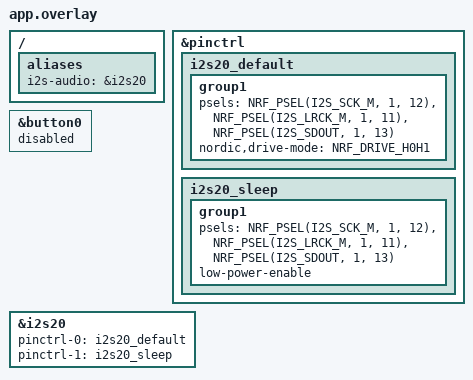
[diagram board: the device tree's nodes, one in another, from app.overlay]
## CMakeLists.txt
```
#
# Copyright (c) 2026 5th Sense
# SPDX-License-Identifier: Apache-2.0
#

cmake_minimum_required(VERSION 3.20.0)

find_package(Zephyr REQUIRED HINTS $ENV{ZEPHYR_BASE})
project(nrf54l15_audio_receiver)

target_sources(app PRIVATE
    src/main.c
    src/audio_i2s.c
    src/audio_stream_service.c
    src/jitter_buffer.c
    src/flash_storage.c
    src/audio_dsp.c
    src/tone_synth.c
    src/adpcm.c
    src/lc3/lc3_dec.c
    src/lc3/lc3_tables.c
)

target_include_directories(app PRIVATE src src/lc3)
```

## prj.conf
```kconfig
#
# Copyright (c) 2026 5th Sense
# nRF54L15 Audio Receiver Configuration
#

# General System & Kernel
CONFIG_MAIN_STACK_SIZE=4096
CONFIG_SYSTEM_WORKQUEUE_STACK_SIZE=4096
CONFIG_BT_RX_STACK_SIZE=4096
CONFIG_HEAP_MEM_POOL_SIZE=32768
CONFIG_FPU=y
CONFIG_EVENTS=y
CONFIG_RING_BUFFER=y

# Logging & Assertions
CONFIG_LOG=y
CONFIG_LOG_DEFAULT_LEVEL=3
CONFIG_LOG_BUFFER_SIZE=4096
CONFIG_CBPRINTF_FP_SUPPORT=y
CONFIG_ASSERT=y

# Bluetooth LE Configuration
CONFIG_BT=y
CONFIG_BT_PERIPHERAL=y
CONFIG_BT_DEVICE_NAME="nRF54L15-Audio-Sink"
CONFIG_BT_DEVICE_APPEARANCE=2064
CONFIG_BT_MAX_CONN=1
CONFIG_BT_MAX_PAIRED=1

# High-Throughput BLE Parameters (16x 502-byte hardware packet buffers)
CONFIG_BT_BUF_ACL_RX_COUNT=16
CONFIG_BT_BUF_ACL_TX_COUNT=16
CONFIG_BT_BUF_ACL_RX_SIZE=502
CONFIG_BT_BUF_ACL_TX_SIZE=502
CONFIG_BT_L2CAP_TX_MTU=498
CONFIG_BT_CTLR_DATA_LENGTH_MAX=251
CONFIG_BT_USER_DATA_LEN_UPDATE=y
CONFIG_BT_USER_PHY_UPDATE=y
CONFIG_BT_AUTO_PHY_UPDATE=y
CONFIG_BT_AUTO_DATA_LEN_UPDATE=y
CONFIG_BT_GATT_CLIENT=n
CONFIG_BT_GATT_DYNAMIC_DB=y

# Bluetooth Controller Tuning for High Data Rate
CONFIG_BT_CTLR_TX_PWR_PLUS_8=y

# I2S Driver for MAX98357A
CONFIG_I2S=y
CONFIG_I2S_NRFX=y

# Flash Storage & LittleFS (For Onboard/External Flash)
CONFIG_FLASH=y
CONFIG_FLASH_MAP=y
CONFIG_FLASH_PAGE_LAYOUT=y
CONFIG_FILE_SYSTEM=y
CONFIG_FILE_SYSTEM_LITTLEFS=y
CONFIG_NORDIC_QSPI_NOR=y
CONFIG_SPI_NOR=y

# Power Management
CONFIG_PM=y
CONFIG_PM_DEVICE=y

# GPIO & Pin Control
CONFIG_GPIO=y
CONFIG_PINCTRL=y
```

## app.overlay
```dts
/*
 * Copyright (c) 2026 5th Sense
 * DeviceTree Overlay for nRF54L15 Audio Receiver with MAX98357A & Storage
 */

/ {
	aliases {
		i2s-audio = &i2s20;
	};
};

/* Pin control configuration for I2S output to MAX98357A */
&pinctrl {
	i2s20_default: i2s20_default {
		group1 {
			psels = <NRF_PSEL(I2S_SCK_M, 1, 12)>,
				<NRF_PSEL(I2S_LRCK_M, 1, 11)>,
				<NRF_PSEL(I2S_SDOUT, 1, 13)>;
			nordic,drive-mode = <NRF_DRIVE_H0H1>;
		};
	};

	i2s20_sleep: i2s20_sleep {
		group1 {
			psels = <NRF_PSEL(I2S_SCK_M, 1, 12)>,
				<NRF_PSEL(I2S_LRCK_M, 1, 11)>,
				<NRF_PSEL(I2S_SDOUT, 1, 13)>;
			low-power-enable;
		};
	};
};

/* Disable button0 on P1.13 so P1.13 is fully dedicated to I2S DIN */
&button0 {
	status = "disabled";
};

/* Enable I2S20 peripheral */
&i2s20 {
	status = "okay";
	pinctrl-0 = <&i2s20_default>;
	pinctrl-1 = <&i2s20_sleep>;
	pinctrl-names = "default", "sleep";
};
```

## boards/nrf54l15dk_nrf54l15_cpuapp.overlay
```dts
/*
 * Copyright (c) 2026 5th Sense
 * Board specific overlay for nRF54L15 DK (PCA10156)
 */

#include "../app.overlay"
```

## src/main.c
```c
/*
 * Copyright (c) 2026 5th Sense
 * nRF54L15 Audio Receiver Main Application
 */

#include <zephyr/kernel.h>
#include <zephyr/logging/log.h>
#include <zephyr/bluetooth/bluetooth.h>
#include <zephyr/bluetooth/conn.h>
#include <zephyr/bluetooth/uuid.h>
#include <zephyr/bluetooth/gatt.h>
#include <zephyr/drivers/gpio.h>

#include "audio_protocol.h"
#include "audio_dsp.h"
#include "jitter_buffer.h"
#include "audio_i2s.h"
#include "flash_storage.h"
#include "audio_stream_service.h"
#include "tone_synth.h"

LOG_MODULE_REGISTER(main, LOG_LEVEL_INF);

/* LED Status Indicator aliases if present on board */
#define LED0_NODE DT_ALIAS(led0)
#define LED1_NODE DT_ALIAS(led1)

#if DT_NODE_HAS_STATUS(LED0_NODE, okay)
static const struct gpio_dt_spec led_conn = GPIO_DT_SPEC_GET(LED0_NODE, gpios);
#endif
#if DT_NODE_HAS_STATUS(LED1_NODE, okay)
static const struct gpio_dt_spec led_play = GPIO_DT_SPEC_GET(LED1_NODE, gpios);
#endif

void main_set_conn_led(bool active)
{
#if DT_NODE_HAS_STATUS(LED0_NODE, okay)
	if (device_is_ready(led_conn.port)) {
		gpio_pin_set_dt(&led_conn, active ? 1 : 0);
	}
#endif
}

void main_set_playback_led(bool active)
{
#if DT_NODE_HAS_STATUS(LED1_NODE, okay)
	if (device_is_ready(led_play.port)) {
		gpio_pin_set_dt(&led_play, active ? 1 : 0);
	}
#endif
}

/* Physical Hardware Buttons from Schematic:
 * SW2 (Button0) = P1.13 (Connected to MAX98357A I2S DIN)
 * SW3 (Button1) = P1.09
 * SW5 (Button2) = P1.08
 * SW6 (Button3) = P0.04
 */
static const struct device *g_gpio0_dev = NULL;
static const struct device *g_gpio1_dev = NULL;
static struct gpio_callback g_btn_cb_gpio1;
static struct gpio_callback g_btn_cb_gpio0;

static int64_t last_button_time = 0;

static void trigger_diagnostic_tune(const char *btn_name)
{
	int64_t now = k_uptime_get();
	if (now - last_button_time < 400) {
		return; /* Debounce 400ms */
	}
	last_button_time = now;

	LOG_INF("[%s Pressed] Playing Diagnostic Melody...", btn_name);
	tone_synth_play_button2_tune();
}

static void button_pressed_cb(const struct device *dev, struct gpio_callback *cb, uint32_t pins)
{
	ARG_UNUSED(cb);

	if (dev == g_gpio1_dev) {
		if (pins & BIT(9)) {
			trigger_diagnostic_tune("SW3 (Button1 / P1.09)");
		} else if (pins & BIT(8)) {
			trigger_diagnostic_tune("SW5 (Button2 / P1.08)");
		}
	} else if (dev == g_gpio0_dev) {
		if (pins & BIT(4)) {
			trigger_diagnostic_tune("SW6 (Button3 / P0.04)");
		}
	}
}

/* BLE Advertising Data */
static const struct bt_data ad[] = {
	BT_DATA_BYTES(BT_DATA_FLAGS, (BT_LE_AD_GENERAL | BT_LE_AD_NO_BREDR)),
	BT_DATA(BT_DATA_NAME_COMPLETE, CONFIG_BT_DEVICE_NAME, sizeof(CONFIG_BT_DEVICE_NAME) - 1),
};

static const struct bt_data sd[] = {
	BT_DATA_BYTES(BT_DATA_UUID128_ALL, BT_UUID_AUDIO_SERVICE_VAL),
	BT_DATA_BYTES(BT_DATA_GAP_APPEARANCE, 0x10, 0x08), /* Generic Media Player / Audio Sink */
};

/* Fast connection parameters: 15ms interval, 0 latency, 4000ms supervision timeout */
static const struct bt_le_conn_param conn_param_fast = {
	.interval_min = BT_GAP_MS_TO_CONN_INTERVAL(15),
	.interval_max = BT_GAP_MS_TO_CONN_INTERVAL(20),
	.latency = 0,
	.timeout = 400,
};

static bool g_is_connected = false;

static void start_advertising(void)
{
	int ret = bt_le_adv_start(BT_LE_ADV_CONN, ad, ARRAY_SIZE(ad), sd, ARRAY_SIZE(sd));
	if (ret && ret != -EALREADY) {
		bt_le_adv_stop();
		ret = bt_le_adv_start(BT_LE_ADV_CONN, ad, ARRAY_SIZE(ad), sd, ARRAY_SIZE(sd));
	}
	if (!ret) {
		LOG_INF("BLE Advertising active as '%s'", CONFIG_BT_DEVICE_NAME);
	}
}

static void connected_cb(struct bt_conn *conn, uint8_t err)
{
	char addr[BT_ADDR_LE_STR_LEN];
	bt_addr_le_to_str(bt_conn_get_dst(conn), addr, sizeof(addr));

	if (err) {
		LOG_ERR("Connection failed (err 0x%02x): %s", err, addr);
		return;
	}

	g_is_connected = true;
	LOG_INF("Connected to peer: %s", addr);

#if DT_NODE_HAS_STATUS(LED0_NODE, okay)
	if (device_is_ready(led_conn.port)) {
		gpio_pin_set_dt(&led_conn, 1);
	}
#endif

	audio_stream_service_on_connected(conn);
}

static void disconnected_cb(struct bt_conn *conn, uint8_t reason)
{
	char addr[BT_ADDR_LE_STR_LEN];
	bt_addr_le_to_str(bt_conn_get_dst(conn), addr, sizeof(addr));

	g_is_connected = false;
	LOG_INF("Disconnected from %s (reason 0x%02x)", addr, reason);

#if DT_NODE_HAS_STATUS(LED0_NODE, okay)
	if (device_is_ready(led_conn.port)) {
		gpio_pin_set_dt(&led_conn, 0);
	}
#endif
#if DT_NODE_HAS_STATUS(LED1_NODE, okay)
	if (device_is_ready(led_play.port)) {
		gpio_pin_set_dt(&led_play, 0);
	}
#endif

	audio_stream_service_on_disconnected(conn);

	/* Restart advertising */
	start_advertising();
}

static void le_phy_updated_cb(struct bt_conn *conn, struct bt_conn_le_phy_info *param)
{
	LOG_INF("LE PHY Updated: TX=%u, RX=%u", param->tx_phy, param->rx_phy);
}

static void le_data_len_updated_cb(struct bt_conn *conn, struct bt_conn_le_data_len_info *info)
{
	LOG_INF("LE Data Length Updated: TX max=%u bytes, RX max=%u bytes",
		info->tx_max_len, info->rx_max_len);
}

BT_CONN_CB_DEFINE(conn_callbacks) = {
	.connected = connected_cb,
	.disconnected = disconnected_cb,
	.le_phy_updated = le_phy_updated_cb,
	.le_data_len_updated = le_data_len_updated_cb,
};

int main(void)
{
	LOG_INF("==================================================");
	LOG_INF("  5th Sense nRF54L15 Audio Receiver & Streamer    ");
	LOG_INF("  Target: nRF54L15 Dev Module + MAX98357A I2S     ");
	LOG_INF("==================================================");

	/* 1. Init LEDs */
#if DT_NODE_HAS_STATUS(LED0_NODE, okay)
	if (device_is_ready(led_conn.port)) {
		gpio_pin_configure_dt(&led_conn, GPIO_OUTPUT_INACTIVE);
	}
#endif
#if DT_NODE_HAS_STATUS(LED1_NODE, okay)
	if (device_is_ready(led_play.port)) {
		gpio_pin_configure_dt(&led_play, GPIO_OUTPUT_INACTIVE);
	}
#endif

	/* 2. Init Buttons: SW3 (P1.09), SW5 (P1.08), SW6 (P0.04) */
	g_gpio1_dev = DEVICE_DT_GET(DT_NODELABEL(gpio1));
	g_gpio0_dev = DEVICE_DT_GET(DT_NODELABEL(gpio0));

	if (g_gpio1_dev && device_is_ready(g_gpio1_dev)) {
		/* SW3 (Button1 / P1.09) */
		gpio_pin_configure(g_gpio1_dev, 9, GPIO_INPUT | GPIO_PULL_UP);
		gpio_pin_interrupt_configure(g_gpio1_dev, 9, GPIO_INT_EDGE_FALLING);

		/* SW5 (Button2 / P1.08) */
		gpio_pin_configure(g_gpio1_dev, 8, GPIO_INPUT | GPIO_PULL_UP);
		gpio_pin_interrupt_configure(g_gpio1_dev, 8, GPIO_INT_EDGE_FALLING);

		gpio_init_callback(&g_btn_cb_gpio1, button_pressed_cb, BIT(9) | BIT(8));
		gpio_add_callback(g_gpio1_dev, &g_btn_cb_gpio1);
		LOG_INF("Buttons SW3 (P1.09) and SW5 (P1.08) configured");
	}

	if (g_gpio0_dev && device_is_ready(g_gpio0_dev)) {
		/* SW6 (Button3 / P0.04) */
		gpio_pin_configure(g_gpio0_dev, 4, GPIO_INPUT | GPIO_PULL_UP);
		gpio_pin_interrupt_configure(g_gpio0_dev, 4, GPIO_INT_EDGE_FALLING);

		gpio_init_callback(&g_btn_cb_gpio0, button_pressed_cb, BIT(4));
		gpio_add_callback(g_gpio0_dev, &g_btn_cb_gpio0);
		LOG_INF("Button SW6 (P0.04) configured");
	}

	/* 3. Init Audio DSP & Jitter Buffer */
	audio_dsp_init();
	jitter_buffer_init();

	/* 4. Init Flash Storage */
	int ret = flash_storage_init();
	if (ret == 0) {
		LOG_INF("Flash storage ready for audio asset caching");
	}

	/* 5. Init I2S Driver for MAX98357A */
	ret = audio_i2s_init();
	if (ret != 0) {
		LOG_ERR("Failed to initialize I2S interface: %d", ret);
	}

	/* 6. Init Tone & Melody Synthesizer */
	tone_synth_init();

	/* 7. Init Audio GATT Service */
	audio_stream_service_init();

	/* 8. Enable Bluetooth */
	ret = bt_enable(NULL);
	if (ret) {
		LOG_ERR("Bluetooth init failed (err %d)", ret);
		return ret;
	}
	LOG_INF("Bluetooth initialized successfully");

	/* 9. Start Advertising */
	start_advertising();

	/* 10. Play Startup Boot Tune on MAX98357A I2S DAC */
	k_msleep(150);
	tone_synth_play_startup_tune();

	/* 11. Housekeeping, Polling & Stats Loop */
	int stats_counter = 0;
	while (1) {
		k_msleep(50);

		/* Button Polling backup (Grounded when pressed -> raw value 0) */
		if (g_gpio1_dev && device_is_ready(g_gpio1_dev)) {
			if (gpio_pin_get_raw(g_gpio1_dev, 9) == 0) {
				trigger_diagnostic_tune("SW3 (Button1 / P1.09)");
			} else if (gpio_pin_get_raw(g_gpio1_dev, 8) == 0) {
				trigger_diagnostic_tune("SW5 (Button2 / P1.08)");
			}
		}
		if (g_gpio0_dev && device_is_ready(g_gpio0_dev)) {
			if (gpio_pin_get_raw(g_gpio0_dev, 4) == 0) {
				trigger_diagnostic_tune("SW6 (Button3 / P0.04)");
			}
		}

		stats_counter++;
		if (stats_counter >= 10) { /* Every 500ms */
			stats_counter = 0;

			/* Watchdog: If disconnected, ensure advertising is continuously running */
			if (!g_is_connected) {
				start_advertising();
			}

			/* Update Play LED */
#if DT_NODE_HAS_STATUS(LED1_NODE, okay)
			if (device_is_ready(led_play.port)) {
				gpio_pin_set_dt(&led_play, audio_i2s_is_active() ? 1 : 0);
			}
#endif
			/* Send periodic stats to connected phone */
			audio_stream_service_send_stats();
		}
	}

	return 0;
}
```

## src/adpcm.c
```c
/*
 * Copyright (c) 2026 5th Sense
 * IMA-ADPCM Audio Decoder Implementation
 */

#include "adpcm.h"

/* Standard IMA-ADPCM Step Table (89 entries) */
static const int16_t step_table[89] = {
	7, 8, 9, 10, 11, 12, 13, 14, 16, 17,
	19, 21, 23, 25, 28, 31, 34, 37, 41, 45,
	50, 55, 60, 66, 73, 80, 88, 97, 107, 118,
	130, 143, 157, 173, 190, 209, 230, 253, 279, 307,
	337, 371, 408, 449, 494, 544, 598, 658, 724, 796,
	876, 963, 1060, 1166, 1282, 1411, 1552, 1707, 1878, 2066,
	2272, 2499, 2749, 3024, 3327, 3660, 4026, 4428, 4871, 5358,
	5894, 6484, 7132, 7845, 8630, 9493, 10442, 11487, 12635, 13899,
	15289, 16818, 18500, 20350, 22385, 24623, 27086, 29794, 32767
};

/* Standard IMA-ADPCM Index Table for 4-bit nibbles */
static const int8_t index_table[16] = {
	-1, -1, -1, -1, 2, 4, 6, 8,
	-1, -1, -1, -1, 2, 4, 6, 8
};

static inline int16_t decode_sample(uint8_t nibble, int16_t *predictor, int8_t *step_index)
{
	int16_t step = step_table[*step_index];
	int32_t diff = step >> 3;

	if (nibble & 4) diff += step;
	if (nibble & 2) diff += (step >> 1);
	if (nibble & 1) diff += (step >> 2);

	int32_t pred = *predictor;
	if (nibble & 8) {
		pred -= diff;
	} else {
		pred += diff;
	}

	/* Clamp to 16-bit signed range */
	if (pred > 32767) pred = 32767;
	else if (pred < -32768) pred = -32768;

	*predictor = (int16_t)pred;

	/* Update step index */
	int8_t idx = *step_index + index_table[nibble & 0x0F];
	if (idx < 0) idx = 0;
	else if (idx > 88) idx = 88;
	*step_index = idx;

	return *predictor;
}

size_t adpcm_decode_frame(const uint8_t *adpcm_data, size_t adpcm_len,
                          int16_t init_predictor, uint8_t init_index,
                          int16_t *out_pcm)
{
	if (!adpcm_data || !out_pcm || adpcm_len == 0) {
		return 0;
	}

	int16_t predictor = init_predictor;
	int8_t step_index = (int8_t)(init_index > 88 ? 88 : init_index);
	size_t out_idx = 0;

	for (size_t i = 0; i < adpcm_len; i++) {
		uint8_t byte = adpcm_data[i];

		/* Lower nibble first */
		out_pcm[out_idx++] = decode_sample(byte & 0x0F, &predictor, &step_index);

		/* Upper nibble second */
		out_pcm[out_idx++] = decode_sample((byte >> 4) & 0x0F, &predictor, &step_index);
	}

	return out_idx;
}
```

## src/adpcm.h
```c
/*
 * Copyright (c) 2026 5th Sense
 * IMA-ADPCM Audio Codec for Ultra-Low Latency BLE Streaming
 */

#ifndef ADPCM_H_
#define ADPCM_H_

#include <stdint.h>
#include <stddef.h>

#ifdef __cplusplus
extern "C" {
#endif

/*
 * Decode IMA-ADPCM buffer into 16-bit linear PCM
 *
 * @param adpcm_data: Pointer to packed 4-bit ADPCM nibbles
 * @param adpcm_len: Length of adpcm_data in bytes
 * @param init_predictor: Initial 16-bit predictor sample from packet header
 * @param init_index: Initial step index (0-88) from packet header
 * @param out_pcm: Output buffer for 16-bit PCM samples (must hold adpcm_len * 2 samples)
 * @return Number of 16-bit PCM samples generated (adpcm_len * 2)
 */
size_t adpcm_decode_frame(const uint8_t *adpcm_data, size_t adpcm_len,
                          int16_t init_predictor, uint8_t init_index,
                          int16_t *out_pcm);

#ifdef __cplusplus
}
#endif

#endif /* ADPCM_H_ */
```

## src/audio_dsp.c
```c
/*
 * Copyright (c) 2026 5th Sense
 * Audio DSP Implementation
 */

#include "audio_dsp.h"
#include <zephyr/kernel.h>
#include <zephyr/logging/log.h>

LOG_MODULE_REGISTER(audio_dsp, LOG_LEVEL_INF);

static uint8_t g_volume_percent = 100;
static int32_t g_volume_gain_q15 = 32768; /* 100% default unity gain */

void audio_dsp_init(void)
{
	audio_dsp_set_volume(100);
	LOG_INF("Audio DSP initialized. Default volume: %u%%", g_volume_percent);
}

void audio_dsp_set_volume(uint8_t volume_percent)
{
	if (volume_percent > 100) {
		volume_percent = 100;
	}
	g_volume_percent = volume_percent;

	/* Logarithmic perception curve mapping to Q15 gain */
	/* gain = (vol/100)^2 * 32768 */
	uint32_t vol_squared = (uint32_t)volume_percent * (uint32_t)volume_percent;
	g_volume_gain_q15 = (int32_t)((vol_squared * 32768U) / 10000U);
}

uint8_t audio_dsp_get_volume(void)
{
	return g_volume_percent;
}

void audio_dsp_process_pcm16(int16_t *samples, size_t num_samples)
{
	if (!samples || num_samples == 0) {
		return;
	}

	if (g_volume_percent == 100) {
		return;
	}

	if (g_volume_percent == 0) {
		memset(samples, 0, num_samples * sizeof(int16_t));
		return;
	}

	for (size_t i = 0; i < num_samples; i++) {
		/* Apply Q15 volume gain */
		int32_t sample = (int32_t)samples[i];
		int32_t scaled = (sample * g_volume_gain_q15) >> 15;

		/* Soft limiter / hard clamp to 16-bit range */
		if (scaled > 32767) {
			scaled = 32767;
		} else if (scaled < -32768) {
			scaled = -32768;
		}

		samples[i] = (int16_t)scaled;
	}
}

void audio_dsp_stereo_to_mono(const int16_t *stereo_in, int16_t *mono_out, size_t num_frames)
{
	if (!stereo_in || !mono_out || num_frames == 0) {
		return;
	}

	for (size_t i = 0; i < num_frames; i++) {
		int32_t left = stereo_in[i * 2];
		int32_t right = stereo_in[i * 2 + 1];
		int32_t mixed = (left + right) / 2;
		mono_out[i] = (int16_t)mixed;
	}
}
```

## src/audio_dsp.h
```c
/*
 * Copyright (c) 2026 5th Sense
 * Audio DSP: Volume Scaling, Soft Limiter, Mixing
 */

#ifndef AUDIO_DSP_H_
#define AUDIO_DSP_H_

#include <stdint.h>
#include <stddef.h>

#ifdef __cplusplus
extern "C" {
#endif

void audio_dsp_init(void);
void audio_dsp_set_volume(uint8_t volume_percent);
uint8_t audio_dsp_get_volume(void);

/* Process 16-bit PCM samples in place: apply volume scaling and soft-clipping */
void audio_dsp_process_pcm16(int16_t *samples, size_t num_samples);

/* Downmix 16-bit stereo interleaved samples to mono in-place or out */
void audio_dsp_stereo_to_mono(const int16_t *stereo_in, int16_t *mono_out, size_t num_frames);

#ifdef __cplusplus
}
#endif

#endif /* AUDIO_DSP_H_ */
```

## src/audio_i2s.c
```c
/*
 * Copyright (c) 2026 5th Sense
 * Zephyr I2S Driver Implementation for MAX98357A DAC
 */

#include "audio_i2s.h"
#include "jitter_buffer.h"
#include "audio_dsp.h"
#include <zephyr/kernel.h>
#include <zephyr/drivers/i2s.h>
#include <zephyr/logging/log.h>

LOG_MODULE_REGISTER(audio_i2s, LOG_LEVEL_INF);

/* Memory slab for I2S DMA TX buffers (640 bytes per block, 8 blocks) */
K_MEM_SLAB_DEFINE_STATIC(i2s_tx_slab, I2S_BLOCK_SIZE_BYTES, I2S_NUM_BLOCKS, 4);

/* I2S Thread definitions */
#define I2S_THREAD_STACK_SIZE 2048
#define I2S_THREAD_PRIORITY   1 /* High priority audio thread */

static K_THREAD_STACK_DEFINE(i2s_thread_stack, I2S_THREAD_STACK_SIZE);
static struct k_thread i2s_thread_data;

static const struct device *g_i2s_dev = NULL;
static struct i2s_config g_i2s_cfg;
static bool g_is_running = false;
static bool g_dma_running = false;
static bool g_i2s_configured = false;

static void i2s_playback_thread(void *arg1, void *arg2, void *arg3);

int audio_i2s_init(void)
{
#if DT_NODE_EXISTS(DT_ALIAS(i2s_audio))
	g_i2s_dev = DEVICE_DT_GET(DT_ALIAS(i2s_audio));
#elif DT_NODE_EXISTS(DT_NODELABEL(i2s20))
	g_i2s_dev = DEVICE_DT_GET(DT_NODELABEL(i2s20));
#elif DT_NODE_EXISTS(DT_NODELABEL(i2s0))
	g_i2s_dev = DEVICE_DT_GET(DT_NODELABEL(i2s0));
#else
	LOG_ERR("No I2S device found in DeviceTree!");
	return -ENODEV;
#endif

	if (!g_i2s_dev || !device_is_ready(g_i2s_dev)) {
		LOG_ERR("I2S device %s is not ready!", g_i2s_dev ? g_i2s_dev->name : "NULL");
		return -ENODEV;
	}

	LOG_INF("I2S device %s found and ready", g_i2s_dev->name);

	/* Configure standard Stereo Philips I2S format (16kHz, 16-bit, 2 Channels for MAX98357A) */
	int ret = audio_i2s_configure(16000, 2, 16);
	if (ret < 0) {
		LOG_ERR("Failed to configure I2S default format: %d", ret);
		return ret;
	}

	/* Start dedicated I2S playback feeder thread */
	k_thread_create(&i2s_thread_data, i2s_thread_stack,
			K_THREAD_STACK_SIZEOF(i2s_thread_stack),
			i2s_playback_thread, NULL, NULL, NULL,
			I2S_THREAD_PRIORITY, 0, K_NO_WAIT);
	k_thread_name_set(&i2s_thread_data, "i2s_feeder");

	return 0;
}

int audio_i2s_configure(uint32_t sample_rate, uint8_t channels, uint8_t bit_depth)
{
	(void)channels;
	if (!g_i2s_dev) {
		return -ENODEV;
	}

	/* Force 2 channels (Stereo) for MAX98357A standard Philips clocking */
	uint8_t ch = 2;
	uint8_t ws = (bit_depth == 24) ? 24 : 16;

	if (g_i2s_configured && g_i2s_cfg.frame_clk_freq == sample_rate &&
	    g_i2s_cfg.channels == ch && g_i2s_cfg.word_size == ws) {
		return 0; /* Already configured to matching parameters */
	}

	if (g_dma_running) {
		i2s_trigger(g_i2s_dev, I2S_DIR_TX, I2S_TRIGGER_DROP);
		g_dma_running = false;
	}

	memset(&g_i2s_cfg, 0, sizeof(g_i2s_cfg));

	/* Standard Philips I2S format, Master mode */
	g_i2s_cfg.word_size = ws;
	g_i2s_cfg.channels = ch;
	g_i2s_cfg.format = I2S_FMT_DATA_FORMAT_I2S | I2S_FMT_CLK_NF_NB;
	g_i2s_cfg.options = I2S_OPT_FRAME_CLK_MASTER | I2S_OPT_BIT_CLK_MASTER;
	g_i2s_cfg.frame_clk_freq = sample_rate;
	g_i2s_cfg.mem_slab = &i2s_tx_slab;
	g_i2s_cfg.block_size = I2S_BLOCK_SIZE_BYTES;
	g_i2s_cfg.timeout = 1000;

	int ret = i2s_configure(g_i2s_dev, I2S_DIR_TX, &g_i2s_cfg);
	if (ret < 0) {
		LOG_ERR("i2s_configure failed: %d", ret);
		return ret;
	}

	g_i2s_configured = true;
	LOG_INF("I2S Configured: Rate=%u Hz, Ch=%u (Stereo MAX98357A), Bits=%u",
		sample_rate, ch, bit_depth);
	return 0;
}

int audio_i2s_start(void)
{
	if (!g_i2s_configured) {
		return -EINVAL;
	}

	g_is_running = true;
	LOG_INF("Audio I2S output enabled");
	return 0;
}

int audio_i2s_stop(void)
{
	g_is_running = false;
	LOG_INF("Audio I2S output stopped (streaming digital silence)");
	return 0;
}

bool audio_i2s_is_active(void)
{
	return g_is_running;
}

static void i2s_playback_thread(void *arg1, void *arg2, void *arg3)
{
	ARG_UNUSED(arg1);
	ARG_UNUSED(arg2);
	ARG_UNUSED(arg3);

	static int16_t s_mono_buf[160]; /* 10ms mono frame @ 16kHz */

	LOG_INF("I2S Feeder thread active");

	while (1) {
		/* Allocate a buffer from memory slab for I2S DMA */
		void *tx_buf = NULL;
		int ret = k_mem_slab_alloc(&i2s_tx_slab, &tx_buf, K_MSEC(100));
		if (ret != 0) {
			k_msleep(2);
			continue;
		}

		int16_t *stereo_out = (int16_t *)tx_buf;

		/* Check if we have audio to play */
		if (g_is_running && jitter_buffer_is_ready_to_play()) {
			/* Pop 10ms mono PCM frame (320 bytes = 160 samples) from jitter buffer */
			size_t read_bytes = jitter_buffer_pop((uint8_t *)s_mono_buf, 320);
			if (read_bytes < 320) {
				memset((uint8_t *)s_mono_buf + read_bytes, 0, 320 - read_bytes);
			}

			/* Duplicate Mono to Stereo (Left = s, Right = s) for MAX98357A */
			for (int i = 0; i < 160; i++) {
				int16_t s = s_mono_buf[i];
				stereo_out[2 * i]     = s;
				stereo_out[2 * i + 1] = s;
			}

			/* Apply digital volume DSP & soft-clipping before DAC */
			audio_dsp_process_pcm16(stereo_out, 320);
		} else {
			/* Stream silence when idle or buffering */
			memset(tx_buf, 0, I2S_BLOCK_SIZE_BYTES);

			if (!g_dma_running) {
				k_mem_slab_free(&i2s_tx_slab, tx_buf);
				k_msleep(10);
				continue;
			}
		}

		/* Send to I2S controller for DMA transmission */
		ret = i2s_write(g_i2s_dev, tx_buf, I2S_BLOCK_SIZE_BYTES);
		if (ret < 0) {
			LOG_WRN("i2s_write failed (%d), resetting DMA state", ret);
			k_mem_slab_free(&i2s_tx_slab, tx_buf);
			if (g_dma_running) {
				i2s_trigger(g_i2s_dev, I2S_DIR_TX, I2S_TRIGGER_DROP);
				g_dma_running = false;
			}
			k_msleep(5);
			continue;
		}

		/* If I2S DMA is not running, trigger START to begin clocking & DMA */
		if (!g_dma_running) {
			int tr_ret = i2s_trigger(g_i2s_dev, I2S_DIR_TX, I2S_TRIGGER_START);
			if (tr_ret == 0) {
				g_dma_running = true;
				LOG_INF("I2S DMA stream started");
			} else {
				LOG_WRN("i2s_trigger START returned %d", tr_ret);
			}
		}
	}
}
```

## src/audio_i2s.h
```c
/*
 * Copyright (c) 2026 5th Sense
 * Zephyr I2S Driver wrapper for MAX98357A DAC
 */

#ifndef AUDIO_I2S_H_
#define AUDIO_I2S_H_

#include <stdint.h>
#include <stdbool.h>

#ifdef __cplusplus
extern "C" {
#endif

/* 10.0ms @ 16kHz Stereo: 160 stereo pairs = 320 samples * 2 bytes = 640 bytes */
#define I2S_BLOCK_SIZE_BYTES    640
#define I2S_NUM_BLOCKS          8

int audio_i2s_init(void);
int audio_i2s_configure(uint32_t sample_rate, uint8_t channels, uint8_t bit_depth);
int audio_i2s_start(void);
int audio_i2s_stop(void);
bool audio_i2s_is_active(void);

#ifdef __cplusplus
}
#endif

#endif /* AUDIO_I2S_H_ */
```

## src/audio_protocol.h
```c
/*
 * Copyright (c) 2026 5th Sense
 * Audio Streaming Protocol Definitions
 */

#ifndef AUDIO_PROTOCOL_H_
#define AUDIO_PROTOCOL_H_

#include <stdint.h>

#ifdef __cplusplus
extern "C" {
#endif

/* 128-bit UUIDs for 5th Sense Audio Service */
#define BT_UUID_AUDIO_SERVICE_VAL \
	BT_UUID_128_ENCODE(0x5f550001, 0x8b43, 0x4f1e, 0x9827, 0x00554c150000)
#define BT_UUID_AUDIO_DATA_CHAR_VAL \
	BT_UUID_128_ENCODE(0x5f550002, 0x8b43, 0x4f1e, 0x9827, 0x00554c150000)
#define BT_UUID_AUDIO_CTRL_CHAR_VAL \
	BT_UUID_128_ENCODE(0x5f550003, 0x8b43, 0x4f1e, 0x9827, 0x00554c150000)
#define BT_UUID_AUDIO_STATS_CHAR_VAL \
	BT_UUID_128_ENCODE(0x5f550004, 0x8b43, 0x4f1e, 0x9827, 0x00554c150000)

/* Protocol Opcodes */
#define AUDIO_OP_DATA               0x01
#define AUDIO_OP_CONTROL            0x02
#define AUDIO_OP_STATS_REQ          0x03

/* Control Commands */
#define AUDIO_CMD_START             0x10
#define AUDIO_CMD_STOP              0x11
#define AUDIO_CMD_PAUSE             0x12
#define AUDIO_CMD_RESUME            0x13
#define AUDIO_CMD_CONFIG            0x14
#define AUDIO_CMD_SET_VOLUME        0x15
#define AUDIO_CMD_PLAY_FLASH_ASSET  0x16
#define AUDIO_CMD_FLASH_WRITE_START 0x17
#define AUDIO_CMD_FLASH_WRITE_CHUNK 0x18
#define AUDIO_CMD_FLASH_WRITE_END   0x19

/* Audio Codec Types */
#define AUDIO_CODEC_PCM_16BIT       0x00
#define AUDIO_CODEC_ADPCM           0x01
#define AUDIO_CODEC_OPUS            0x02
#define AUDIO_CODEC_SBC             0x03
#define AUDIO_CODEC_LC3             0x04

/* Audio Stream Modes */
#define AUDIO_MODE_FILE             0x00
#define AUDIO_MODE_SYSTEM_SPEAKER   0x01
#define AUDIO_MODE_TTS              0x02

/* Default Audio Configuration */
#define AUDIO_DEFAULT_SAMPLE_RATE   16000
#define AUDIO_DEFAULT_CHANNELS      1
#define AUDIO_DEFAULT_BIT_DEPTH     16

#pragma pack(push, 1)

/* Audio Data Packet Header (6 bytes) */
struct audio_data_header {
	uint8_t opcode;       /* AUDIO_OP_DATA (0x01) */
	uint8_t seq_num;      /* Sequence number 0-255 */
	uint8_t codec;        /* AUDIO_CODEC_LC3 (0x04), ADPCM (0x01), PCM (0x00) */
	uint8_t init_index;   /* ADPCM step index (0-88) or LC3 frame length / flags */
	int16_t init_pred;    /* ADPCM initial predictor or LC3 reserved */
};

/* Audio Config Payload */
struct audio_config_payload {
	uint32_t sample_rate; /* e.g. 16000, 24000, 44100, 48000 */
	uint8_t channels;     /* 1 = Mono, 2 = Stereo */
	uint8_t bit_depth;    /* 16 bits */
	uint8_t codec;        /* AUDIO_CODEC_* */
	uint8_t stream_mode;  /* AUDIO_MODE_* */
};

/* Audio Stats Payload (Firmware -> App Notify) */
struct audio_stats_payload {
	uint8_t buffer_percent;  /* 0 - 100% */
	uint8_t volume;          /* 0 - 100% */
	uint16_t underrun_count; /* Number of buffer underruns */
	uint32_t packets_received;
	uint32_t bytes_played;
	uint8_t is_playing;
	uint8_t reserved[3];
};

#pragma pack(pop)

#ifdef __cplusplus
}
#endif

#endif /* AUDIO_PROTOCOL_H_ */
```

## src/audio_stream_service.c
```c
/*
 * Copyright (c) 2026 5th Sense
 * Bluetooth LE Audio Streaming GATT Service
 */

#include "audio_stream_service.h"
#include "audio_i2s.h"
#include "jitter_buffer.h"
#include "audio_dsp.h"
#include "flash_storage.h"
#include "main.h"
#include <zephyr/kernel.h>
#include <zephyr/bluetooth/bluetooth.h>
#include <zephyr/bluetooth/gatt.h>
#include <zephyr/bluetooth/uuid.h>
#include <zephyr/logging/log.h>
#include <string.h>

LOG_MODULE_REGISTER(audio_svc, LOG_LEVEL_INF);

/* Custom 128-bit UUIDs */
static struct bt_uuid_128 audio_svc_uuid = BT_UUID_INIT_128(BT_UUID_AUDIO_SERVICE_VAL);
static struct bt_uuid_128 audio_data_uuid = BT_UUID_INIT_128(BT_UUID_AUDIO_DATA_CHAR_VAL);
static struct bt_uuid_128 audio_ctrl_uuid = BT_UUID_INIT_128(BT_UUID_AUDIO_CTRL_CHAR_VAL);
static struct bt_uuid_128 audio_stats_uuid = BT_UUID_INIT_128(BT_UUID_AUDIO_STATS_CHAR_VAL);

static struct bt_conn *g_current_conn = NULL;
static bool g_stats_notify_enabled = false;

/* Forward declarations */
static ssize_t write_audio_data(struct bt_conn *conn, const struct bt_gatt_attr *attr,
				const void *buf, uint16_t len, uint16_t offset, uint8_t flags);
static ssize_t write_audio_ctrl(struct bt_conn *conn, const struct bt_gatt_attr *attr,
				const void *buf, uint16_t len, uint16_t offset, uint8_t flags);
static ssize_t read_audio_stats(struct bt_conn *conn, const struct bt_gatt_attr *attr,
				void *buf, uint16_t len, uint16_t offset);
static void stats_ccc_cfg_changed(const struct bt_gatt_attr *attr, uint16_t value);

/* GATT Service Definition */
BT_GATT_SERVICE_DEFINE(audio_svc,
	BT_GATT_PRIMARY_SERVICE(&audio_svc_uuid),

	/* Audio Data Characteristic: Write Without Response */
	BT_GATT_CHARACTERISTIC(&audio_data_uuid.uuid,
			       BT_GATT_CHRC_WRITE_WITHOUT_RESP | BT_GATT_CHRC_WRITE,
			       BT_GATT_PERM_WRITE,
			       NULL, write_audio_data, NULL),

	/* Audio Control Characteristic: Write & Write Without Response */
	BT_GATT_CHARACTERISTIC(&audio_ctrl_uuid.uuid,
			       BT_GATT_CHRC_WRITE | BT_GATT_CHRC_WRITE_WITHOUT_RESP,
			       BT_GATT_PERM_WRITE,
			       NULL, write_audio_ctrl, NULL),

	/* Audio Stats Characteristic: Read & Notify */
	BT_GATT_CHARACTERISTIC(&audio_stats_uuid.uuid,
			       BT_GATT_CHRC_READ | BT_GATT_CHRC_NOTIFY,
			       BT_GATT_PERM_READ,
			       read_audio_stats, NULL, NULL),
	BT_GATT_CCC(stats_ccc_cfg_changed, BT_GATT_PERM_READ | BT_GATT_PERM_WRITE),
);

#include "adpcm.h"
#include "lc3/lc3.h"

/* Static memory allocation for LC3 decoder instance (8KB aligned) */
static uint8_t g_lc3_dec_mem[8192] __aligned(4);
static lc3_decoder_t g_lc3_decoder = NULL;
static uint32_t g_current_sample_rate = 16000;
static uint8_t g_expected_seq_num = 0;
static bool g_seq_initialized = false;

static void ensure_lc3_decoder(uint32_t sample_rate)
{
	if (!g_lc3_decoder || g_current_sample_rate != sample_rate) {
		g_current_sample_rate = sample_rate;
		g_lc3_decoder = lc3_setup_decoder(10000, sample_rate, 0, g_lc3_dec_mem);
		LOG_INF("LC3 Decoder initialized: %u Hz (10.0ms frames, %d samples)",
			sample_rate, lc3_frame_samples(10000, sample_rate));
	}
}

/* Callback when client writes audio PCM/LC3 data chunks */
static ssize_t write_audio_data(struct bt_conn *conn, const struct bt_gatt_attr *attr,
				const void *buf, uint16_t len, uint16_t offset, uint8_t flags)
{
	ARG_UNUSED(conn);
	ARG_UNUSED(attr);
	ARG_UNUSED(offset);
	ARG_UNUSED(flags);

	if (len < sizeof(struct audio_data_header)) {
		return BT_GATT_ERR(BT_ATT_ERR_INVALID_ATTRIBUTE_LEN);
	}

	struct audio_data_header hdr;
	memcpy(&hdr, buf, sizeof(hdr));

	if (hdr.opcode != AUDIO_OP_DATA) {
		return BT_GATT_ERR(BT_ATT_ERR_VALUE_NOT_ALLOWED);
	}

	const uint8_t *payload = (const uint8_t *)buf + sizeof(struct audio_data_header);
	size_t payload_len = len - sizeof(struct audio_data_header);

	if (payload_len > 0) {
		if (hdr.codec == AUDIO_CODEC_LC3) {
			ensure_lc3_decoder(g_current_sample_rate);

			int samples_per_frame = lc3_frame_samples(10000, g_current_sample_rate);
			if (samples_per_frame > 0 && samples_per_frame <= 480 && g_lc3_decoder) {
				static int16_t s_decoded_pcm[480];

				/* 1. Packet Loss Concealment (PLC) for missed frames */
				if (g_seq_initialized) {
					uint8_t lost = (hdr.seq_num >= g_expected_seq_num) ?
						(hdr.seq_num - g_expected_seq_num) :
						(256 + hdr.seq_num - g_expected_seq_num);

					if (lost > 0 && lost <= 4) {
						LOG_WRN("LC3 Packet loss (%u frames)! Running PLC...", lost);
						for (uint8_t p = 0; p < lost; p++) {
							lc3_decode(g_lc3_decoder, NULL, 0,
								   LC3_PCM_FORMAT_S16, s_decoded_pcm, 1);
							jitter_buffer_push((const uint8_t *)s_decoded_pcm,
									   samples_per_frame * sizeof(int16_t),
									   (g_expected_seq_num + p) & 0xFF);
						}
					}
				}

				/* 2. Decode Current LC3 Frame */
				int ret = lc3_decode(g_lc3_decoder, payload, payload_len,
						     LC3_PCM_FORMAT_S16, s_decoded_pcm, 1);
				if (ret == 0) {
					jitter_buffer_push((const uint8_t *)s_decoded_pcm,
							   samples_per_frame * sizeof(int16_t),
							   hdr.seq_num);
				} else {
					LOG_WRN("lc3_decode failed: %d", ret);
				}

				g_expected_seq_num = (hdr.seq_num + 1) & 0xFF;
				g_seq_initialized = true;
			}
		} else if (hdr.codec == AUDIO_CODEC_ADPCM) {
			if (payload_len >= 3) {
				int16_t init_pred = (int16_t)((uint16_t)payload[0] | ((uint16_t)payload[1] << 8));
				int8_t init_idx = (int8_t)payload[2];
				const uint8_t *adpcm_stream = payload + 3;
				size_t adpcm_len = payload_len - 3;

				static struct ima_adpcm_state s_adpcm_state;
				ima_adpcm_init_state(&s_adpcm_state, init_pred, init_idx);

				static int16_t s_pcm_buf[512];
				size_t num_samples = adpcm_len * 2;
				if (num_samples > 512) num_samples = 512;

				ima_adpcm_decode_block(&s_adpcm_state, adpcm_stream, adpcm_len, s_pcm_buf);
				jitter_buffer_push((const uint8_t *)s_pcm_buf, num_samples * sizeof(int16_t), hdr.seq_num);
			}
		} else {
			/* Linear PCM */
			jitter_buffer_push(payload, payload_len, hdr.seq_num);
		}
	}

	return len;
}

/* Callback when client writes to control characteristic */
static ssize_t write_audio_ctrl(struct bt_conn *conn, const struct bt_gatt_attr *attr,
				const void *buf, uint16_t len, uint16_t offset, uint8_t flags)
{
	ARG_UNUSED(conn);
	ARG_UNUSED(attr);
	ARG_UNUSED(offset);
	ARG_UNUSED(flags);

	if (len < 1) {
		return BT_GATT_ERR(BT_ATT_ERR_INVALID_ATTRIBUTE_LEN);
	}

	const uint8_t *data = (const uint8_t *)buf;
	uint8_t cmd = data[0];

	LOG_INF("Audio Control Command received: 0x%02X (len=%u)", cmd, len);

	switch (cmd) {
	case AUDIO_CMD_START:
		jitter_buffer_reset();
		g_seq_initialized = false;
		g_expected_seq_num = 0;
		if (g_lc3_decoder) lc3_decoder_reset(g_lc3_decoder);
		audio_i2s_start();
		main_set_playback_led(true);
		LOG_INF("Playback started by client");
		break;

	case AUDIO_CMD_STOP:
		audio_i2s_stop();
		jitter_buffer_reset();
		g_seq_initialized = false;
		g_expected_seq_num = 0;
		if (g_lc3_decoder) lc3_decoder_reset(g_lc3_decoder);
		main_set_playback_led(false);
		LOG_INF("Playback stopped by client");
		break;

	case AUDIO_CMD_PAUSE:
		audio_i2s_stop();
		main_set_playback_led(false);
		LOG_INF("Playback paused by client");
		break;

	case AUDIO_CMD_RESUME:
		audio_i2s_start();
		main_set_playback_led(true);
		LOG_INF("Playback resumed by client");
		break;

	case AUDIO_CMD_CONFIG:
		if (len >= 1 + sizeof(struct audio_config_payload)) {
			struct audio_config_payload cfg;
			memcpy(&cfg, data + 1, sizeof(cfg));
			LOG_INF("Config received: Rate=%u, Ch=%u, Bits=%u, Codec=%u, Mode=%u",
				cfg.sample_rate, cfg.channels, cfg.bit_depth, cfg.codec, cfg.stream_mode);
			g_current_sample_rate = cfg.sample_rate;
			ensure_lc3_decoder(cfg.sample_rate);
			audio_i2s_configure(cfg.sample_rate, cfg.channels, cfg.bit_depth);
			jitter_buffer_reset();
			g_seq_initialized = false;
			g_expected_seq_num = 0;
			audio_i2s_start();
		}
		break;

	case AUDIO_CMD_SET_VOLUME:
		if (len >= 2) {
			uint8_t vol = data[1];
			audio_dsp_set_volume(vol);
			LOG_INF("Volume set to %u%%", vol);
		}
		break;

	case AUDIO_CMD_PLAY_FLASH_ASSET:
		if (len >= 2) {
			uint8_t asset_id = data[1];
			flash_storage_play_asset(asset_id);
			audio_i2s_start();
		}
		break;

	default:
		LOG_WRN("Unknown control command: 0x%02X", cmd);
		break;
	}

	return len;
}

/* Callback when client reads stats characteristic */
static ssize_t read_audio_stats(struct bt_conn *conn, const struct bt_gatt_attr *attr,
				void *buf, uint16_t len, uint16_t offset)
{
	ARG_UNUSED(conn);

	struct jitter_buffer_stats j_stats;
	jitter_buffer_get_stats(&j_stats);

	struct audio_stats_payload payload = {
		.buffer_percent = j_stats.fill_percent,
		.volume = audio_dsp_get_volume(),
		.underrun_count = j_stats.underrun_count,
		.packets_received = j_stats.packets_received,
		.bytes_played = j_stats.total_bytes_read,
		.is_playing = audio_i2s_is_active() ? 1 : 0
	};

	return bt_gatt_attr_read(conn, attr, buf, len, offset, &payload, sizeof(payload));
}

static void stats_ccc_cfg_changed(const struct bt_gatt_attr *attr, uint16_t value)
{
	ARG_UNUSED(attr);
	g_stats_notify_enabled = (value == BT_GATT_CCC_NOTIFY);
	LOG_INF("Stats notification %s", g_stats_notify_enabled ? "enabled" : "disabled");
}

int audio_stream_service_init(void)
{
	ensure_lc3_decoder(16000);
	LOG_INF("Audio Stream GATT Service registered");
	return 0;
}

void audio_stream_service_on_connected(struct bt_conn *conn)
{
	if (g_current_conn) {
		bt_conn_unref(g_current_conn);
		g_current_conn = NULL;
	}
	g_current_conn = bt_conn_ref(conn);
	g_stats_notify_enabled = false;
	g_seq_initialized = false;
	g_expected_seq_num = 0;
	jitter_buffer_reset();
	if (g_lc3_decoder) {
		lc3_decoder_reset(g_lc3_decoder);
	}
	main_set_playback_led(false);
	LOG_INF("Client connected to Audio Service (Session Cleaned)");
}

void audio_stream_service_on_disconnected(struct bt_conn *conn)
{
	ARG_UNUSED(conn);
	if (g_current_conn) {
		bt_conn_unref(g_current_conn);
		g_current_conn = NULL;
	}
	g_stats_notify_enabled = false;
	g_seq_initialized = false;
	g_expected_seq_num = 0;
	audio_i2s_stop();
	jitter_buffer_reset();
	if (g_lc3_decoder) {
		lc3_decoder_reset(g_lc3_decoder);
	}
	main_set_playback_led(false);
	LOG_INF("Client disconnected from Audio Service (Session Reset)");
}

int audio_stream_service_send_stats(void)
{
	if (!g_current_conn || !g_stats_notify_enabled) {
		return 0;
	}

	struct jitter_buffer_stats j_stats;
	jitter_buffer_get_stats(&j_stats);

	struct audio_stats_payload payload = {
		.buffer_percent = j_stats.fill_percent,
		.volume = audio_dsp_get_volume(),
		.underrun_count = j_stats.underrun_count,
		.packets_received = j_stats.packets_received,
		.bytes_played = j_stats.total_bytes_read,
		.is_playing = audio_i2s_is_active() ? 1 : 0
	};

	return bt_gatt_notify_uuid(g_current_conn, &audio_stats_uuid.uuid, audio_svc.attrs, &payload, sizeof(payload));
}
```

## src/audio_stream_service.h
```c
/*
 * Copyright (c) 2026 5th Sense
 * BLE Custom Audio GATT Streaming Service
 */

#ifndef AUDIO_STREAM_SERVICE_H_
#define AUDIO_STREAM_SERVICE_H_

#include <stdint.h>
#include <stdbool.h>
#include <zephyr/bluetooth/bluetooth.h>
#include <zephyr/bluetooth/conn.h>
#include <zephyr/bluetooth/gatt.h>
#include "audio_protocol.h"

#ifdef __cplusplus
extern "C" {
#endif

int audio_stream_service_init(void);

/* Called when BLE connection state changes */
void audio_stream_service_on_connected(struct bt_conn *conn);
void audio_stream_service_on_disconnected(struct bt_conn *conn);

/* Push periodic statistics to connected client */
int audio_stream_service_send_stats(void);

#ifdef __cplusplus
}
#endif

#endif /* AUDIO_STREAM_SERVICE_H_ */
```

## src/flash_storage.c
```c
/*
 * Copyright (c) 2026 5th Sense
 * External NOR Flash (QSPI/SPI) Storage Driver for nRF54L15
 */

#include "flash_storage.h"
#include "jitter_buffer.h"
#include <zephyr/kernel.h>
#include <zephyr/drivers/flash.h>
#include <zephyr/storage/flash_map.h>
#include <zephyr/logging/log.h>

LOG_MODULE_REGISTER(flash_storage, LOG_LEVEL_INF);

static const struct device *g_flash_dev = NULL;
static bool g_flash_ready = false;

/* Structure stored at beginning of an asset region */
struct asset_header {
	uint32_t magic;       /* 0x534E5335 "5SNS" */
	uint32_t sample_rate;
	uint32_t size_bytes;
	uint8_t channels;
	uint8_t bit_depth;
	uint8_t reserved[6];
};

#define ASSET_MAGIC 0x534E5335

static uint32_t get_asset_base_addr(uint8_t asset_id)
{
	/* Divide flash area into 256KB slots */
	return FLASH_AUDIO_BASE_OFFSET + ((uint32_t)asset_id * FLASH_MAX_ASSET_SIZE);
}

int flash_storage_init(void)
{
#if DT_NODE_EXISTS(DT_ALIAS(audio_flash))
	g_flash_dev = DEVICE_DT_GET(DT_ALIAS(audio_flash));
#elif DT_NODE_EXISTS(DT_NODELABEL(mx25r6435f))
	g_flash_dev = DEVICE_DT_GET(DT_NODELABEL(mx25r6435f));
#elif DT_NODE_EXISTS(DT_NODELABEL(rram_controller))
	g_flash_dev = DEVICE_DT_GET(DT_NODELABEL(rram_controller));
#elif DT_NODE_EXISTS(DT_CHOSEN(zephyr_flash))
	g_flash_dev = DEVICE_DT_GET_OR_NULL(DT_CHOSEN(zephyr_flash));
#else
	g_flash_dev = NULL;
#endif

	if (!g_flash_dev || !device_is_ready(g_flash_dev)) {
		LOG_WRN("External/Internal flash storage not ready or not found. Flash caching disabled.");
		g_flash_ready = false;
		return -ENODEV;
	}

	g_flash_ready = true;
	LOG_INF("Flash storage initialized: %s", g_flash_dev->name);
	return 0;
}

bool flash_storage_is_ready(void)
{
	return g_flash_ready;
}

int flash_storage_erase_asset(uint8_t asset_id, size_t total_size)
{
	if (!g_flash_ready) {
		return -ENODEV;
	}

	uint32_t addr = get_asset_base_addr(asset_id);
	size_t erase_size = (total_size + FLASH_AUDIO_SECTOR_SIZE - 1) & ~(FLASH_AUDIO_SECTOR_SIZE - 1);
	if (erase_size > FLASH_MAX_ASSET_SIZE) {
		erase_size = FLASH_MAX_ASSET_SIZE;
	}

	LOG_INF("Erasing flash asset %u at 0x%08X (size %u bytes)", asset_id, addr, (uint32_t)erase_size);
	int ret = flash_erase(g_flash_dev, addr, erase_size);
	if (ret != 0) {
		LOG_ERR("flash_erase failed: %d", ret);
	}
	return ret;
}

int flash_storage_write_asset(uint8_t asset_id, uint32_t offset, const uint8_t *data, size_t len)
{
	if (!g_flash_ready) {
		return -ENODEV;
	}

	uint32_t addr = get_asset_base_addr(asset_id) + sizeof(struct asset_header) + offset;
	int ret = flash_write(g_flash_dev, addr, data, len);
	if (ret != 0) {
		LOG_ERR("flash_write failed at 0x%08X: %d", addr, ret);
	}
	return ret;
}

int flash_storage_read_asset(uint8_t asset_id, uint32_t offset, uint8_t *dest, size_t len)
{
	if (!g_flash_ready) {
		return -ENODEV;
	}

	uint32_t addr = get_asset_base_addr(asset_id) + sizeof(struct asset_header) + offset;
	return flash_read(g_flash_dev, addr, dest, len);
}

int flash_storage_play_asset(uint8_t asset_id)
{
	if (!g_flash_ready) {
		return -ENODEV;
	}

	uint32_t base_addr = get_asset_base_addr(asset_id);
	struct asset_header hdr;
	int ret = flash_read(g_flash_dev, base_addr, &hdr, sizeof(hdr));
	if (ret != 0 || hdr.magic != ASSET_MAGIC) {
		LOG_WRN("Asset %u not valid or empty (magic=0x%08X)", asset_id, hdr.magic);
		return -ENOENT;
	}

	LOG_INF("Playing flash asset %u (size=%u bytes, rate=%u Hz)",
		asset_id, hdr.size_bytes, hdr.sample_rate);

	jitter_buffer_reset();

	/* Read in chunks of 512 bytes and push to jitter buffer */
	uint8_t chunk_buf[512];
	uint32_t bytes_left = hdr.size_bytes;
	uint32_t offset = 0;
	uint8_t seq = 0;

	while (bytes_left > 0) {
		size_t to_read = (bytes_left > sizeof(chunk_buf)) ? sizeof(chunk_buf) : bytes_left;
		ret = flash_storage_read_asset(asset_id, offset, chunk_buf, to_read);
		if (ret != 0) {
			break;
		}

		jitter_buffer_push(chunk_buf, to_read, seq++);
		offset += to_read;
		bytes_left -= to_read;
	}

	return 0;
}
```

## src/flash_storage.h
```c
/*
 * Copyright (c) 2026 5th Sense
 * Onboard/External Flash Memory Storage Manager for nRF54L15
 */

#ifndef FLASH_STORAGE_H_
#define FLASH_STORAGE_H_

#include <stdint.h>
#include <stdbool.h>
#include <stddef.h>

#ifdef __cplusplus
extern "C" {
#endif

#define FLASH_AUDIO_SECTOR_SIZE   4096
#define FLASH_AUDIO_BASE_OFFSET   0x000000 /* Base offset in external flash */
#define FLASH_MAX_ASSET_SIZE      (256 * 1024) /* 256 KB max cached asset */

int flash_storage_init(void);
bool flash_storage_is_ready(void);

/* Write audio chunk to flash (offset relative to asset slot) */
int flash_storage_write_asset(uint8_t asset_id, uint32_t offset, const uint8_t *data, size_t len);

/* Read audio chunk from flash */
int flash_storage_read_asset(uint8_t asset_id, uint32_t offset, uint8_t *dest, size_t len);

/* Erase asset storage region */
int flash_storage_erase_asset(uint8_t asset_id, size_t total_size);

/* Stream an asset from flash directly into the jitter buffer for playback */
int flash_storage_play_asset(uint8_t asset_id);

#ifdef __cplusplus
}
#endif

#endif /* FLASH_STORAGE_H_ */
```

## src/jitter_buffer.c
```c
/*
 * Copyright (c) 2026 5th Sense
 * Audio Jitter Buffer Implementation
 */

#include "jitter_buffer.h"
#include <zephyr/kernel.h>
#include <zephyr/sys/ring_buffer.h>
#include <zephyr/logging/log.h>
#include <string.h>

LOG_MODULE_REGISTER(jitter_buf, LOG_LEVEL_INF);

static uint8_t g_ring_buf_raw[JITTER_BUFFER_CAPACITY_BYTES];
static struct ring_buf g_ring_buf;
static K_MUTEX_DEFINE(g_buf_mutex);

static struct jitter_buffer_stats g_stats;
static uint8_t g_last_seq_num = 0;
static bool g_has_received_first_packet = false;

void jitter_buffer_init(void)
{
	k_mutex_lock(&g_buf_mutex, K_FOREVER);
	ring_buf_init(&g_ring_buf, sizeof(g_ring_buf_raw), g_ring_buf_raw);
	memset(&g_stats, 0, sizeof(g_stats));
	g_stats.capacity = JITTER_BUFFER_CAPACITY_BYTES;
	g_has_received_first_packet = false;
	k_mutex_unlock(&g_buf_mutex);

	LOG_INF("Jitter buffer initialized (Capacity: %d bytes)", JITTER_BUFFER_CAPACITY_BYTES);
}

void jitter_buffer_reset(void)
{
	k_mutex_lock(&g_buf_mutex, K_FOREVER);
	ring_buf_reset(&g_ring_buf);
	g_stats.bytes_available = 0;
	g_stats.bytes_free = JITTER_BUFFER_CAPACITY_BYTES;
	g_stats.fill_percent = 0;
	g_stats.is_prebuffered = false;
	g_has_received_first_packet = false;
	k_mutex_unlock(&g_buf_mutex);

	LOG_INF("Jitter buffer reset");
}

size_t jitter_buffer_push(const uint8_t *data, size_t len, uint8_t seq_num)
{
	if (!data || len == 0) {
		return 0;
	}

	k_mutex_lock(&g_buf_mutex, K_FOREVER);

	/* Check sequence continuity for packet loss detection */
	if (g_has_received_first_packet) {
		uint8_t expected = (g_last_seq_num + 1) & 0xFF;
		if (seq_num != expected) {
			uint8_t lost = (seq_num >= expected) ? (seq_num - expected) : (256 + seq_num - expected);
			g_stats.packets_dropped += lost;
			LOG_WRN("Packet loss detected! Expected seq %u, got %u (Lost: %u)",
				expected, seq_num, lost);
		}
	} else {
		g_has_received_first_packet = true;
	}
	g_last_seq_num = seq_num;
	g_stats.packets_received++;

	/* Write to ring buffer */
	uint32_t written = ring_buf_put(&g_ring_buf, data, len);
	if (written < len) {
		/* Buffer overflow / overrun */
		LOG_WRN("Jitter buffer overflow! Dropped %u bytes", (uint32_t)(len - written));
	}

	g_stats.total_bytes_written += written;
	g_stats.bytes_available = ring_buf_size_get(&g_ring_buf);
	g_stats.bytes_free = ring_buf_space_get(&g_ring_buf);
	g_stats.fill_percent = (uint8_t)((g_stats.bytes_available * 100) / g_stats.capacity);

	if (!g_stats.is_prebuffered && g_stats.bytes_available >= JITTER_BUFFER_PREBUFFER_BYTES) {
		g_stats.is_prebuffered = true;
		LOG_INF("Prebuffer threshold reached (%u bytes). Playback ready!", (uint32_t)g_stats.bytes_available);
	}

	k_mutex_unlock(&g_buf_mutex);
	return written;
}

size_t jitter_buffer_pop(uint8_t *dest, size_t requested_len)
{
	if (!dest || requested_len == 0) {
		return 0;
	}

	k_mutex_lock(&g_buf_mutex, K_FOREVER);

	uint32_t read_bytes = ring_buf_get(&g_ring_buf, dest, requested_len);

	if (read_bytes < requested_len) {
		/* Underrun condition - fill remaining with silence (0) */
		memset(dest + read_bytes, 0, requested_len - read_bytes);
		g_stats.underrun_count++;
		g_stats.is_prebuffered = false; /* Force re-buffer */
	}

	g_stats.total_bytes_read += read_bytes;
	g_stats.bytes_available = ring_buf_size_get(&g_ring_buf);
	g_stats.bytes_free = ring_buf_space_get(&g_ring_buf);
	g_stats.fill_percent = (uint8_t)((g_stats.bytes_available * 100) / g_stats.capacity);

	k_mutex_unlock(&g_buf_mutex);
	return requested_len;
}

bool jitter_buffer_is_ready_to_play(void)
{
	k_mutex_lock(&g_buf_mutex, K_FOREVER);
	bool ready = (g_stats.bytes_available >= 320);
	k_mutex_unlock(&g_buf_mutex);
	return ready;
}

void jitter_buffer_get_stats(struct jitter_buffer_stats *out_stats)
{
	if (!out_stats) {
		return;
	}
	k_mutex_lock(&g_buf_mutex, K_FOREVER);
	memcpy(out_stats, &g_stats, sizeof(struct jitter_buffer_stats));
	k_mutex_unlock(&g_buf_mutex);
}
```
